# HTNB32L-XXX register map
File version: 0.9
HTNB32L-XXX M3
CPU: CM3 r0p0, little endian, no MPU, no FPU, 3 interrupt priority bits
Registers are 32-bit, read-write, reset 0x0 unless marked. A register's access mark holds for its fields unless they carry their own. Offsets are from the block's base; lines under a group give offsets from that group; [hi:lo] are bit positions; {n}, {i} and the like mark numbered series; 'fields as' and 'values as' point back to an identical list; <NAME> marks a mode.

## Memory map
0x20098000 GPIO size 0xFFF — General Purpose I/O
0x40000000 WWDT size 0xFFF — Windowed Watchdog Timer (WWDT)
0x40004000 TIMER0 size 0xFFF — Timer0/1/2/3
0x40008000 TIMER1 size 0xFFF
0x4000C000 UART0 size 0xFFF — UART0/2/3
0x40010000 UART1 size 0xFFF
0x40014000 PWM0 size 0xFFF — Pulse Width Modulators (PWM0/1)
0x40018000 PWM1 size 0xFFF
0x4001C000 I2C0 size 0xFFF — I2C bus interface
0x40024000 RTC size 0xFFF — Real Time Clock (RTC)
0x40028080 GPIOINT size 0xFFF — GPIO
0x4002C000 IOCON size 0xFFF — IOCON pin configuration
0x40030000 SSP1 size 0xFFF — SSP1 controller
0x40034000 ADC size 0xFFF — Analog-to-Digital Converter (ADC)
0x40038000 CANAFRAM size 0xFFF — CAN acceptance filter RAM
0x4003C000 CANAF size 0xFFF — CAN controller acceptance filter
0x40040000 CCAN size 0xFFF — Central CAN controller
0x40044000 CAN1 size 0xFFF — CAN1 controller
0x40048000 CAN2 size 0xFFF
0x4005C000 I2C1 size 0xFFF
0x40088000 SSP0 size 0x300 — SSP controller
0x4008C000 DAC size 0xFFF — Digital-to-Analog Converter (DAC)
0x40090000 TIMER2 size 0xFFF
0x40094000 TIMER3 size 0xFFF
0x40098000 UART2 size 0xFFF
0x4009C000 UART3 size 0xFFF
0x400A0000 I2C2 size 0xFFF
0x400A4000 UART4 size 0xFFF
0x400A8000 I2S size 0xFFF — I2S interface
0x400AC000 SSP2 size 0xFFF
0x400B8000 MCPWM size 0xFFF — Motor Control PWM
0x400BC000 QEI size 0xFFF — Quadrature Encoder Interface (QEI)
0x400C0000 SDMMC size 0xFFFF — SD card interface
0x400FC000 SYSCON size 0xFFF — System and clock control

## Interrupts
0 WWDT
1 TIMER0
2 TIMER1
3 TIMER2
4 TIMER3
5 UART0
6 UART1
7 UART2
8 UART3
9 PWM1
10 I2C0
11 I2C1
12 I2C2
14 SSP0
15 SSP1
17 RTC
18 EINT0 (SYSCON)
19 EINT1 (SYSCON)
20 EINT2 (SYSCON)
21 EINT3 (SYSCON)
22 ADC
23 BOD (SYSCON)
25 CAN (CAN1)
27 I2S
29 SDMMC
30 MCPWM
31 QEI
35 UART4
36 SSP2
38 GPIOINT
39 PWM0

## GPIO — General Purpose I/O
Base 0x20098000
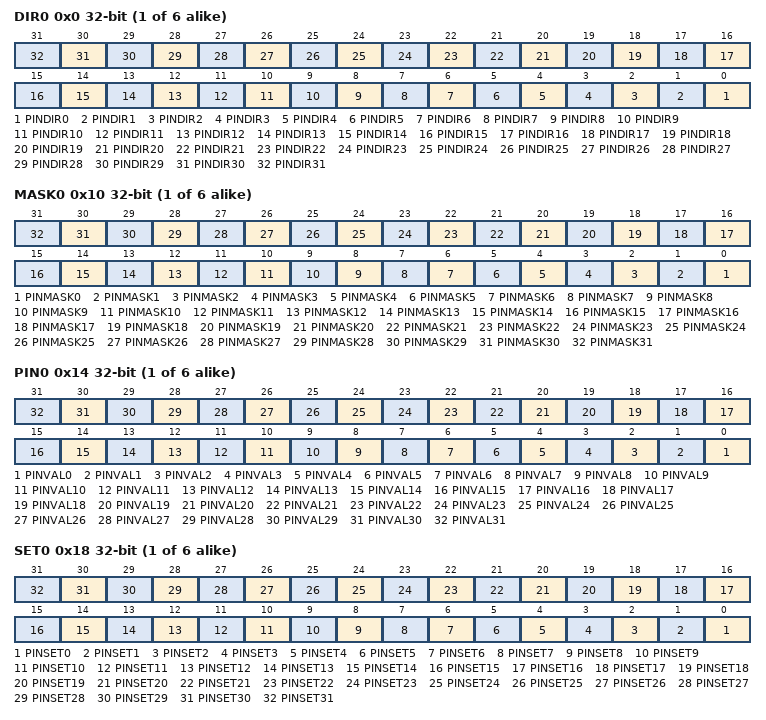
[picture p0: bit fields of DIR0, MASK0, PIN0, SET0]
{0x0+0x20*i} DIR{i} (i=0..5) — GPIO Port0 Direction control register.
  [n] PINDIR{n} (n=0..31) — Fast GPIO Direction PORTx control bits. Bit 0 in DIRx controls pin Px[0], bit 31 in DIRx controls pin Px[31]. 0 = Controlled pin is input. 1 = Controlled pin is output.
{0x10+0x20*i} MASK{i} (i=0..5) — Mask register for Port0.
  [n] PINMASK{n} (n=0..31) — Fast GPIO physical pin access control. 0 = Controlled pin is affected by writes to the port's SETx, CLRx, and PINx register(s). Current state of the pin can be read from the PINx register. 1 = Controlled pin is not affected by writes into the port's SETx, CLRx and PINx register(s). When the PINx register is read, this bit will not be updated with the state of the physical pin.
{0x14+0x20*i} PIN{i} (i=0..5) — Port0 Pin value register using FIOMASK.
  [n] PINVAL{n} (n=0..31) — Fast GPIO output value Set bits. Bit 0 in PINx corresponds to pin Px[0], bit 31 in PINx corresponds to pin Px[31]. 0 = Controlled pin output is set to LOW. 1 = Controlled pin output is set to HIGH.
{0x18+0x20*i} SET{i} (i=0..5) — Port0 Output Set register using FIOMASK.
  [n] PINSET{n} (n=0..31) — Fast GPIO output value Set bits. Bit 0 in SETx controls pin Px[0], bit 31 in SETx controls pin Px[31]. 0 = Controlled pin output is unchanged. 1 = Controlled pin output is set to HIGH.
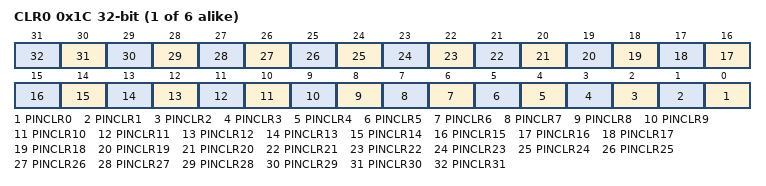
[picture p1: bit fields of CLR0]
{0x1C+0x20*i} CLR{i} (i=0..5) wo — Port0 Output Clear register using FIOMASK.
  [n] PINCLR{n} (n=0..31) — Fast GPIO output value Clear bits. Bit 0 in CLRx controls pin Px[0], bit 31 in CLRx controls pin Px[31]. 0 = Controlled pin output is unchanged. 1 = Controlled pin output is set to LOW.

## WWDT — Windowed Watchdog Timer (WWDT)
Base 0x40000000
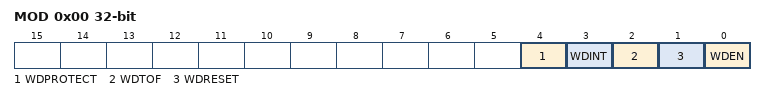
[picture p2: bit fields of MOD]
0x00 MOD — Watchdog mode register. This register determines the basic mode and status of the Watchdog Timer.
  [4] WDPROTECT — Watchdog update mode. This bit is Set Only. See Section WDPROTECT.
    0=CHANGE (The watchdog reload value (WDTC) can be changed at any time.); 1=CHANGE_W_CNT (The watchdog reload value (WDTC) can be changed only after the counter is below the value of WDWARNINT and WDWINDOW. Note: this mode is intended for use only when WDRESET =1.)
  [3] WDINT — Watchdog interrupt flag. Set when the timer reaches the value in WDWARNINT. Cleared by software. See Section WDINT.
  [2] WDTOF — Watchdog time-out flag. Set when the watchdog timer times out, by a feed error, or by events associated with WDPROTECT, cleared by software. Causes a chip reset if WDRESET = 1. See Section WDTOF.
  [1] WDRESET — Watchdog reset enable bit. This bit is Set Only. See Table 652.
    0=NORESET (A watchdog timeout will not cause a chip reset.); 1=RESET (A watchdog timeout will cause a chip reset.)
  [0] WDEN — Watchdog enable bit. This bit is Set Only. See Table 652.
    0=STOP (The watchdog timer is stopped.); 1=RUN (The watchdog timer is running.)
0x04 TC reset 0xFF — Watchdog timer constant register. The value in this register determines the time-out value.
  [23:0] Count — Watchdog time-out interval.
0x08 FEED wo reset not defined — Watchdog feed sequence register. Writing 0xAA followed by 0x55 to this register reloads the Watchdog timer with the value contained in WDTC.
  [7:0] Feed — Feed value should be 0xAA followed by 0x55.
0x0C TV ro reset 0xFF — Watchdog timer value register. This register reads out the current value of the Watchdog timer.
  [23:0] Count — Counter timer value.
0x14 WARNINT — Watchdog Warning Interrupt compare value.
  [9:0] WARNINT — Watchdog warning interrupt compare value.
0x18 WINDOW reset 0xFFFFFF — Watchdog Window compare value.
  [23:0] WINDOW — Watchdog window value.
